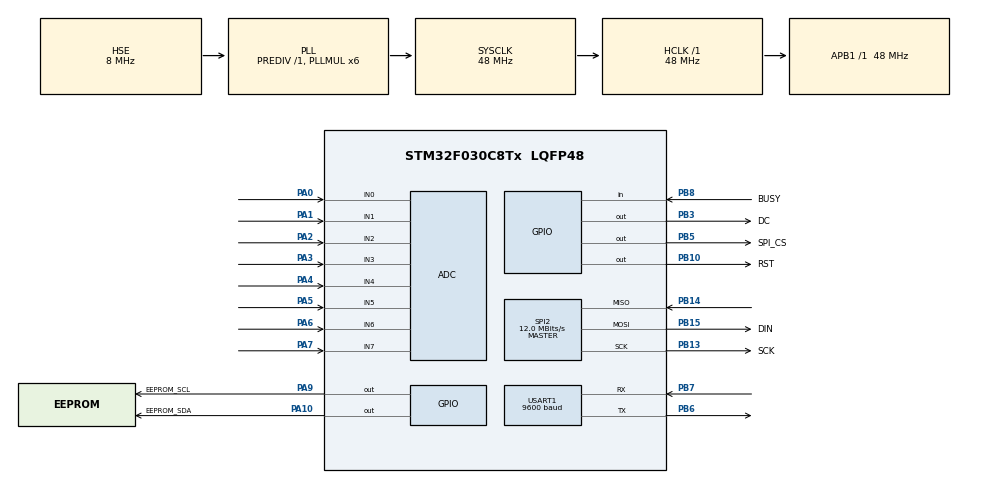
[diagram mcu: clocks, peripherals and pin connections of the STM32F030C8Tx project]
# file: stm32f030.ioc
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ADC.ContinuousConvMode=ENABLE
ADC.DMAContinuousRequests=ENABLE
ADC.EOCSelection=ADC_EOC_SEQ_CONV
ADC.SamplingTime=ADC_SAMPLETIME_239CYCLES_5
Dma.ADC.0.Direction=DMA_PERIPH_TO_MEMORY
Dma.ADC.0.Instance=DMA1_Channel1
Dma.ADC.0.MemDataAlignment=DMA_MDATAALIGN_HALFWORD
Dma.ADC.0.MemInc=DMA_MINC_ENABLE
Dma.ADC.0.Mode=DMA_CIRCULAR
Dma.ADC.0.PeriphDataAlignment=DMA_PDATAALIGN_HALFWORD
Dma.ADC.0.PeriphInc=DMA_PINC_DISABLE
Dma.ADC.0.Priority=DMA_PRIORITY_LOW
Dma.Request0=ADC
Mcu.Family=STM32F0
Mcu.Name=STM32F030C8Tx
Mcu.Package=LQFP48
NVIC.ADC1_IRQn=true\:0\:0\:false\:false\:true\:true\:true\:true
NVIC.DMA1_Channel1_IRQn=true\:0\:0\:false\:false\:true\:false\:true\:true
NVIC.SPI2_IRQn=true\:0\:0\:false\:false\:true\:true\:true\:true
NVIC.USART1_IRQn=true\:0\:0\:false\:false\:true\:true\:true\:true
PA0.Mode=IN0
PA0.Signal=ADC_IN0
PA1.Mode=IN1
PA1.Signal=ADC_IN1
PA10.GPIO_Label=EEPROM_SDA
PA10.GPIO_ModeDefaultOutputPP=GPIO_MODE_OUTPUT_PP
PA10.GPIO_PuPd=GPIO_PULLUP
PA10.GPIO_Speed=GPIO_SPEED_FREQ_HIGH
PA10.Signal=GPIO_Output
PA13.Mode=Serial_Wire
PA13.Signal=SYS_SWDIO
PA14.Mode=Serial_Wire
PA14.Signal=SYS_SWCLK
PA2.Mode=IN2
PA2.Signal=ADC_IN2
PA3.Mode=IN3
PA3.Signal=ADC_IN3
PA4.Mode=IN4
PA4.Signal=ADC_IN4
PA5.Mode=IN5
PA5.Signal=ADC_IN5
PA6.Mode=IN6
PA6.Signal=ADC_IN6
PA7.Mode=IN7
PA7.Signal=ADC_IN7
PA9.GPIO_Label=EEPROM_SCL
PA9.GPIO_ModeDefaultOutputPP=GPIO_MODE_OUTPUT_PP
PA9.GPIO_PuPd=GPIO_PULLUP
PA9.GPIO_Speed=GPIO_SPEED_FREQ_HIGH
PA9.Signal=GPIO_Output
PB10.GPIO_Label=RST
PB10.GPIO_Speed=GPIO_SPEED_FREQ_HIGH
PB10.Signal=GPIO_Output
PB13.GPIO_Label=SCK
PB13.Mode=Full_Duplex_Master
PB13.Signal=SPI2_SCK
PB14.Mode=Full_Duplex_Master
PB14.Signal=SPI2_MISO
PB15.GPIO_Label=DIN
PB15.Mode=Full_Duplex_Master
PB15.Signal=SPI2_MOSI
PB3.GPIO_Label=DC
PB3.GPIO_Speed=GPIO_SPEED_FREQ_HIGH
PB3.Signal=GPIO_Output
PB5.GPIO_Label=SPI_CS
PB5.GPIO_Speed=GPIO_SPEED_FREQ_HIGH
PB5.Signal=GPIO_Output
PB6.Mode=Asynchronous
PB6.Signal=USART1_TX
PB7.Mode=Asynchronous
PB7.Signal=USART1_RX
PB8.GPIO_Label=BUSY
PB8.Signal=GPIO_Input
PF0-OSC_IN.Mode=HSE-External-Oscillator
PF0-OSC_IN.Signal=RCC_OSC_IN
PF1-OSC_OUT.Mode=HSE-External-Oscillator
PF1-OSC_OUT.Signal=RCC_OSC_OUT
ProjectManager.HeapSize=0x200
ProjectManager.StackSize=0x400
ProjectManager.TargetToolchain=STM32CubeIDE
RCC.AHBFreq_Value=48000000
RCC.APB1Freq_Value=48000000
RCC.APB1TimFreq_Value=48000000
RCC.HCLKFreq_Value=48000000
RCC.PLLMUL=RCC_PLL_MUL6
RCC.PLLSourceVirtual=RCC_PLLSOURCE_HSE
RCC.SYSCLKFreq_VALUE=48000000
RCC.SYSCLKSource=RCC_SYSCLKSOURCE_PLLCLK
SPI2.BaudRatePrescaler=SPI_BAUDRATEPRESCALER_4
SPI2.CalculateBaudRate=12.0 MBits/s
SPI2.DataSize=SPI_DATASIZE_8BIT
SPI2.Direction=SPI_DIRECTION_2LINES
SPI2.Mode=SPI_MODE_MASTER
SPI2.VirtualType=VM_MASTER
USART1.BaudRate=9600
USART1.VirtualMode-Asynchronous=VM_ASYNC
board=custom

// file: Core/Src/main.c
/* USER CODE BEGIN Header */
/**
  ******************************************************************************
  * @file           : main.c
  * @brief          : Main program body
  ******************************************************************************
  * @attention
  *
  * Copyright (c) 2026 STMicroelectronics.
  * All rights reserved.
  *
  * This software is licensed under terms that can be found in the LICENSE file
  * in the root directory of this software component.
  * If no LICENSE file comes with this software, it is provided AS-IS.
  *
  ******************************************************************************
  */
/* USER CODE END Header */
#include "main.h"

/* USER CODE BEGIN Includes */
#include "startup.h"
/* USER CODE END Includes */

ADC_HandleTypeDef hadc;
DMA_HandleTypeDef hdma_adc;

SPI_HandleTypeDef hspi2;

UART_HandleTypeDef huart1;

void SystemClock_Config(void);
static void MX_GPIO_Init(void);
static void MX_DMA_Init(void);
static void MX_USART1_UART_Init(void);
static void MX_SPI2_Init(void);
static void MX_ADC_Init(void);

int main(void)
{

  /* MCU Configuration--------------------------------------------------------*/

  /* Reset of all peripherals, Initializes the Flash interface and the Systick. */
  HAL_Init();

  /* Configure the system clock */
  SystemClock_Config();

  /* Initialize all configured peripherals */
  MX_GPIO_Init();
  MX_DMA_Init();
  MX_USART1_UART_Init();
  MX_SPI2_Init();
  MX_ADC_Init();
  /* USER CODE BEGIN 2 */
  setup();
  /* USER CODE END 2 */

  /* Infinite loop */
  while (1)
  {

    /* USER CODE BEGIN 3 */
	loop();
  }
  /* USER CODE END 3 */
}

void SystemClock_Config(void)
{
  RCC_OscInitTypeDef RCC_OscInitStruct = {0};
  RCC_ClkInitTypeDef RCC_ClkInitStruct = {0};
  RCC_PeriphCLKInitTypeDef PeriphClkInit = {0};

  /** Initializes the RCC Oscillators according to the specified parameters
  * in the RCC_OscInitTypeDef structure.
  */
  RCC_OscInitStruct.OscillatorType = RCC_OSCILLATORTYPE_HSI14|RCC_OSCILLATORTYPE_HSE;
  RCC_OscInitStruct.HSEState = RCC_HSE_ON;
  RCC_OscInitStruct.HSI14State = RCC_HSI14_ON;
  RCC_OscInitStruct.HSI14CalibrationValue = 16;
  RCC_OscInitStruct.PLL.PLLState = RCC_PLL_ON;
  RCC_OscInitStruct.PLL.PLLSource = RCC_PLLSOURCE_HSE;
  RCC_OscInitStruct.PLL.PLLMUL = RCC_PLL_MUL6;
  RCC_OscInitStruct.PLL.PREDIV = RCC_PREDIV_DIV1;
  if (HAL_RCC_OscConfig(&RCC_OscInitStruct) != HAL_OK)
  {
    Error_Handler();
  }

  /** Initializes the CPU, AHB and APB buses clocks
  */
  RCC_ClkInitStruct.ClockType = RCC_CLOCKTYPE_HCLK|RCC_CLOCKTYPE_SYSCLK
                              |RCC_CLOCKTYPE_PCLK1;
  RCC_ClkInitStruct.SYSCLKSource = RCC_SYSCLKSOURCE_PLLCLK;
  RCC_ClkInitStruct.AHBCLKDivider = RCC_SYSCLK_DIV1;
  RCC_ClkInitStruct.APB1CLKDivider = RCC_HCLK_DIV1;

  if (HAL_RCC_ClockConfig(&RCC_ClkInitStruct, FLASH_LATENCY_1) != HAL_OK)
  {
    Error_Handler();
  }
  PeriphClkInit.PeriphClockSelection = RCC_PERIPHCLK_USART1;
  PeriphClkInit.Usart1ClockSelection = RCC_USART1CLKSOURCE_PCLK1;
  if (HAL_RCCEx_PeriphCLKConfig(&PeriphClkInit) != HAL_OK)
  {
    Error_Handler();
  }
}

static void MX_ADC_Init(void)
{

  ADC_ChannelConfTypeDef sConfig = {0};

  /** Configure the global features of the ADC (Clock, Resolution, Data Alignment and number of conversion)
  */
  hadc.Instance = ADC1;
  hadc.Init.ClockPrescaler = ADC_CLOCK_ASYNC_DIV1;
  hadc.Init.Resolution = ADC_RESOLUTION_12B;
  hadc.Init.DataAlign = ADC_DATAALIGN_RIGHT;
  hadc.Init.ScanConvMode = ADC_SCAN_DIRECTION_FORWARD;
  hadc.Init.EOCSelection = ADC_EOC_SEQ_CONV;
  hadc.Init.LowPowerAutoWait = DISABLE;
  hadc.Init.LowPowerAutoPowerOff = DISABLE;
  hadc.Init.ContinuousConvMode = ENABLE;
  hadc.Init.DiscontinuousConvMode = DISABLE;
  hadc.Init.ExternalTrigConv = ADC_SOFTWARE_START;
  hadc.Init.ExternalTrigConvEdge = ADC_EXTERNALTRIGCONVEDGE_NONE;
  hadc.Init.DMAContinuousRequests = ENABLE;
  hadc.Init.Overrun = ADC_OVR_DATA_PRESERVED;
  if (HAL_ADC_Init(&hadc) != HAL_OK)
  {
    Error_Handler();
  }

  /** Configure for the selected ADC regular channel to be converted.
  */
  sConfig.Channel = ADC_CHANNEL_0;
  sConfig.Rank = ADC_RANK_CHANNEL_NUMBER;
  sConfig.SamplingTime = ADC_SAMPLETIME_239CYCLES_5;
  if (HAL_ADC_ConfigChannel(&hadc, &sConfig) != HAL_OK)
  {
    Error_Handler();
  }

  /** Configure for the selected ADC regular channel to be converted.
  */
  sConfig.Channel = ADC_CHANNEL_1;
  if (HAL_ADC_ConfigChannel(&hadc, &sConfig) != HAL_OK)
  {
    Error_Handler();
  }

  /** Configure for the selected ADC regular channel to be converted.
  */
  sConfig.Channel = ADC_CHANNEL_2;
  if (HAL_ADC_ConfigChannel(&hadc, &sConfig) != HAL_OK)
  {
    Error_Handler();
  }

  /** Configure for the selected ADC regular channel to be converted.
  */
  sConfig.Channel = ADC_CHANNEL_3;
  if (HAL_ADC_ConfigChannel(&hadc, &sConfig) != HAL_OK)
  {
    Error_Handler();
  }

  /** Configure for the selected ADC regular channel to be converted.
  */
  sConfig.Channel = ADC_CHANNEL_4;
  if (HAL_ADC_ConfigChannel(&hadc, &sConfig) != HAL_OK)
  {
    Error_Handler();
  }

  /** Configure for the selected ADC regular channel to be converted.
  */
  sConfig.Channel = ADC_CHANNEL_5;
  if (HAL_ADC_ConfigChannel(&hadc, &sConfig) != HAL_OK)
  {
    Error_Handler();
  }

  /** Configure for the selected ADC regular channel to be converted.
  */
  sConfig.Channel = ADC_CHANNEL_6;
  if (HAL_ADC_ConfigChannel(&hadc, &sConfig) != HAL_OK)
  {
    Error_Handler();
  }

  /** Configure for the selected ADC regular channel to be converted.
  */
  sConfig.Channel = ADC_CHANNEL_7;
  if (HAL_ADC_ConfigChannel(&hadc, &sConfig) != HAL_OK)
  {
    Error_Handler();
  }

}

static void MX_SPI2_Init(void)
{

  /* SPI2 parameter configuration*/
  hspi2.Instance = SPI2;
  hspi2.Init.Mode = SPI_MODE_MASTER;
  hspi2.Init.Direction = SPI_DIRECTION_2LINES;
  hspi2.Init.DataSize = SPI_DATASIZE_8BIT;
  hspi2.Init.CLKPolarity = SPI_POLARITY_LOW;
  hspi2.Init.CLKPhase = SPI_PHASE_1EDGE;
  hspi2.Init.NSS = SPI_NSS_SOFT;
  hspi2.Init.BaudRatePrescaler = SPI_BAUDRATEPRESCALER_4;
  hspi2.Init.FirstBit = SPI_FIRSTBIT_MSB;
  hspi2.Init.TIMode = SPI_TIMODE_DISABLE;
  hspi2.Init.CRCCalculation = SPI_CRCCALCULATION_DISABLE;
  hspi2.Init.CRCPolynomial = 7;
  hspi2.Init.CRCLength = SPI_CRC_LENGTH_DATASIZE;
  hspi2.Init.NSSPMode = SPI_NSS_PULSE_ENABLE;
  if (HAL_SPI_Init(&hspi2) != HAL_OK)
  {
    Error_Handler();
  }

}

static void MX_USART1_UART_Init(void)
{

  huart1.Instance = USART1;
  huart1.Init.BaudRate = 9600;
  huart1.Init.WordLength = UART_WORDLENGTH_8B;
  huart1.Init.StopBits = UART_STOPBITS_1;
  huart1.Init.Parity = UART_PARITY_NONE;
  huart1.Init.Mode = UART_MODE_TX_RX;
  huart1.Init.HwFlowCtl = UART_HWCONTROL_NONE;
  huart1.Init.OverSampling = UART_OVERSAMPLING_16;
  huart1.Init.OneBitSampling = UART_ONE_BIT_SAMPLE_DISABLE;
  huart1.AdvancedInit.AdvFeatureInit = UART_ADVFEATURE_NO_INIT;
  if (HAL_UART_Init(&huart1) != HAL_OK)
  {
    Error_Handler();
  }

}

static void MX_DMA_Init(void)
{

  /* DMA controller clock enable */
  __HAL_RCC_DMA1_CLK_ENABLE();

  /* DMA interrupt init */
  /* DMA1_Channel1_IRQn interrupt configuration */
  HAL_NVIC_SetPriority(DMA1_Channel1_IRQn, 0, 0);
  HAL_NVIC_EnableIRQ(DMA1_Channel1_IRQn);

}

static void MX_GPIO_Init(void)
{
  GPIO_InitTypeDef GPIO_InitStruct = {0};

  /* GPIO Ports Clock Enable */
  __HAL_RCC_GPIOF_CLK_ENABLE();
  __HAL_RCC_GPIOA_CLK_ENABLE();
  __HAL_RCC_GPIOB_CLK_ENABLE();

  /*Configure GPIO pin Output Level */
  HAL_GPIO_WritePin(GPIOB, RST_Pin|DC_Pin|SPI_CS_Pin, GPIO_PIN_RESET);

  /*Configure GPIO pin Output Level */
  HAL_GPIO_WritePin(GPIOA, EEPROM_SCL_Pin|EEPROM_SDA_Pin, GPIO_PIN_RESET);

  /*Configure GPIO pins : RST_Pin DC_Pin SPI_CS_Pin */
  GPIO_InitStruct.Pin = RST_Pin|DC_Pin|SPI_CS_Pin;
  GPIO_InitStruct.Mode = GPIO_MODE_OUTPUT_PP;
  GPIO_InitStruct.Pull = GPIO_NOPULL;
  GPIO_InitStruct.Speed = GPIO_SPEED_FREQ_HIGH;
  HAL_GPIO_Init(GPIOB, &GPIO_InitStruct);

  /*Configure GPIO pins : EEPROM_SCL_Pin EEPROM_SDA_Pin */
  GPIO_InitStruct.Pin = EEPROM_SCL_Pin|EEPROM_SDA_Pin;
  GPIO_InitStruct.Mode = GPIO_MODE_OUTPUT_PP;
  GPIO_InitStruct.Pull = GPIO_PULLUP;
  GPIO_InitStruct.Speed = GPIO_SPEED_FREQ_HIGH;
  HAL_GPIO_Init(GPIOA, &GPIO_InitStruct);

  /*Configure GPIO pin : BUSY_Pin */
  GPIO_InitStruct.Pin = BUSY_Pin;
  GPIO_InitStruct.Mode = GPIO_MODE_INPUT;
  GPIO_InitStruct.Pull = GPIO_NOPULL;
  HAL_GPIO_Init(BUSY_GPIO_Port, &GPIO_InitStruct);

}

void Error_Handler(void)
{
  __disable_irq();
  while (1)
  {
  }
}
